# CC3220SF register map
Vendor: Texas Instruments; Series: Wireless Connectivity MCU; File version: 1
CPU: CM4 r1p0, little endian, no MPU, no FPU, 8 interrupt priority bits
Registers are 32-bit, read-write, reset 0x0 unless marked. A register's access mark holds for its fields unless they carry their own. Offsets are from the block's base; [hi:lo] are bit positions; {n}, {i} and the like mark numbered series.

## I2S
Base 0x4401C000
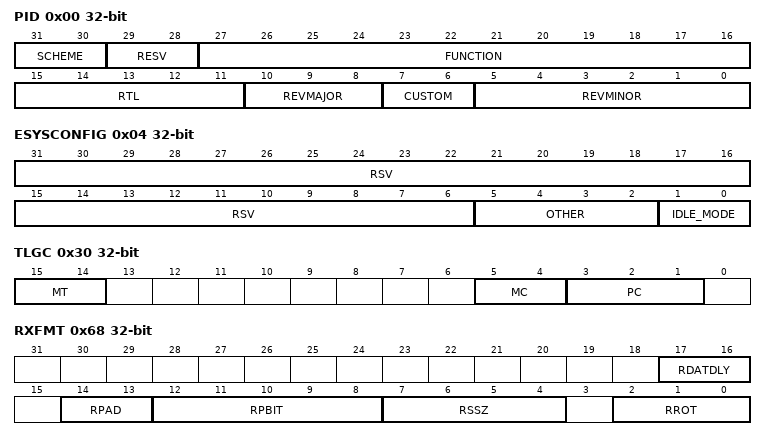
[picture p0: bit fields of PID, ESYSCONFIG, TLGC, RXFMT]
0x00 PID
  [31:30] SCHEME
  [29:28] RESV
  [27:16] FUNCTION — McASP
  [15:11] RTL
  [10:8] REVMAJOR
  [7:6] CUSTOM — non-custom
  [5:0] REVMINOR
0x04 ESYSCONFIG — Power Idle SYSCONFIG register.
  [31:6] RSV — Reserved as per PDR 3.5
  [5:2] OTHER — Reserved for future expansion
  [1:0] IDLE_MODE
0x10 PFUNC
0x14 PDIR
0x18 PDOUT
0x1C PDIN_PDSET — The pin data input register (PDIN) holds the I/O pin state of each of the McASP pins. PDIN allows the actual value of the pin to be read regardless of the state of PFUNC and PDIR. The pin data set register (PDSET) is an alias of the pin data output register (PDOUT) for writes only. Writing a 1 to the PDSET bit sets the corresponding bit in PDOUT and if PFUNC = 1 (GPIO function) and PDIR = 1 (output) drives a logic high on the pin.
0x20 PDCLR — The pin data clear register (PDCLR) is an alias of the pin data output register (PDOUT) for writes only. Writing a 1 to the PDCLR bit clears the corresponding bit in PDOUT and if PFUNC = 1 (GPIO function) and PDIR = 1 (output) drives a logic low on the pin.
0x30 TLGC — for IODFT
  [15:14] MT — MISR on/off trigger command 0x0 0x1 0x2 0x3
  [5:4] MC — States of MISR 0x0 0x1 0x2 0x3
  [3:1] PC — Pattern code 0x0 0x1 0x2 0x3 0x4 0x5 0x6 0x7
0x34 TLMR — for IODFT
0x38 TLEC — for IODFT
0x44 GBLCTL
0x48 AMUTE
  [1:0] MUTEN — AMUTE pin enable 0x0 0x1 0x2
0x4C LBCTL
  [3:2] MODE — Loop back clock source generator 0x0 0x1 0x2 0x3
0x50 TXDITCTL
0x60 GBLCTLR
0x64 RXMASK
0x68 RXFMT
  [17:16] RDATDLY — RCV Frame sync delay 0x0 0 Bit delay 0x1 1 Bit delay 0x2 2 Bit delay
  [14:13] RPAD — Pad value 0x0 0x1 0x2
  [12:8] RPBIT — Pad bit position
  [7:4] RSSZ — RCV slot Size 0x0 0x1 0x2 0x3 0x4 0x5 0x6 0x7 0x8 0x9 0xA 0xB 0xC 0xD 0xE 0xF
  [2:0] RROT — Right Rotate Value 0x0 0x1 0x2 0x3 0x4 0x5 0x6 0x7
0x6C RXFMCTL
  [15:7] RMOD — RCV Frame sync mode
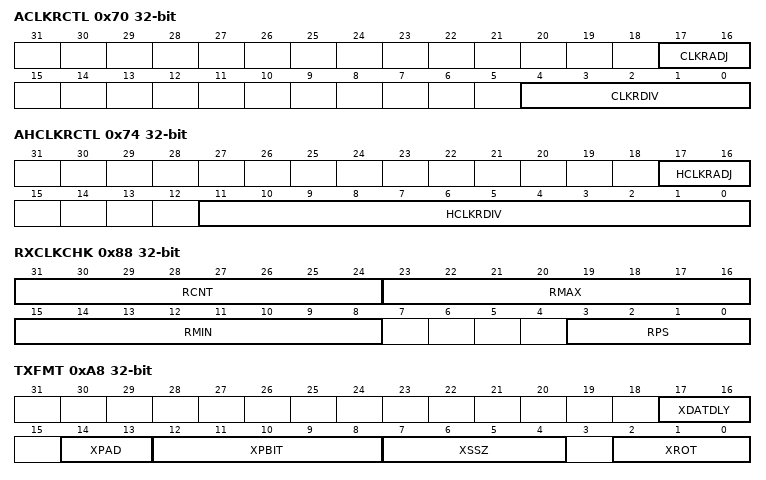
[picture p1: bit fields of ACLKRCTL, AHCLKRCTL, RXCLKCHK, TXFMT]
0x70 ACLKRCTL
  [17:16] CLKRADJ
  [4:0] CLKRDIV — RCV clock devide ratio
0x74 AHCLKRCTL
  [17:16] HCLKRADJ
  [11:0] HCLKRDIV — RCV clock Divide Ratio
0x78 RXTDM
0x7C EVTCTLR
0x80 RXSTAT
0x84 RXTDMSLOT
  [9:0] RSLOTCNT — Current RCV time slot count
0x88 RXCLKCHK
  [31:24] RCNT — RCV clock count value
  [23:16] RMAX — RCV clock maximum boundary
  [15:8] RMIN — RCV clock minimum boundary
  [3:0] RPS — RCV clock check prescaler 0x0 0x1 0x2 0x3 0x4 0x5 0x6 0x7 0x8
0x8C REVTCTL
0xA0 GBLCTLX
0xA4 TXMASK
0xA8 TXFMT
  [17:16] XDATDLY — XMT Frame sync delay 0x0 0 Bit delay 0x1 1 Bit delay 0x2 2 Bit delay
  [14:13] XPAD — Pad value 0x0 0x1 0x2
  [12:8] XPBIT — Pad bit position
  [7:4] XSSZ — XMT slot Size 0x0 0x1 0x2 0x3 0x4 0x5 0x6 0x7 0x8 0x9 0xA 0xB 0xC 0xD 0xE 0xF
  [2:0] XROT — Right Rotate Value 0x0 0x1 0x2 0x3 0x4 0x5 0x6 0x7
0xAC TXFMCTL
  [15:7] XMOD — XMT Frame sync mode
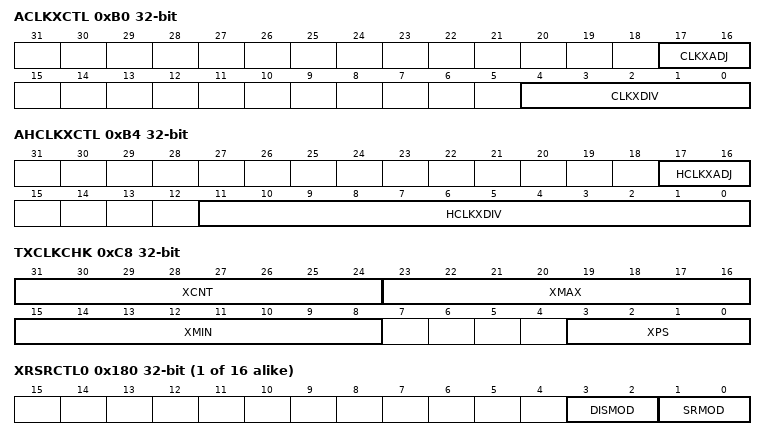
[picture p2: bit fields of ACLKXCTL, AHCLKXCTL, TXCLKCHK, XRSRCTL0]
0xB0 ACLKXCTL
  [17:16] CLKXADJ
  [4:0] CLKXDIV — XMT clock devide ratio
0xB4 AHCLKXCTL
  [17:16] HCLKXADJ
  [11:0] HCLKXDIV — XMT clock Divide Ratio
0xB8 TXTDM
0xBC EVTCTLX
0xC0 TXSTAT
0xC4 TXTDMSLOT
  [9:0] XSLOTCNT — Current XMT time slot count during reset the value of this register is 0b0101111111 (0x17f) and after reset 0
0xC8 TXCLKCHK
  [31:24] XCNT — XMT clock count value
  [23:16] XMAX — XMT clock maximum boundary
  [15:8] XMIN — XMT clock minimum boundary
  [3:0] XPS — XMT clock check prescaler 0x0 0x1 0x2 0x3 0x4 0x5 0x6 0x7 0x8
0xCC XEVTCTL
0xD0 CLKADJEN
{0x100+4i} DITCSRA{i} (i=0..5)
{0x118+4i} DITCSRB{i} (i=0..5)
{0x130+4i} DITUDRA{i} (i=0..5)
{0x148+4i} DITUDRB{i} (i=0..5)
{0x180+4i} XRSRCTL{i} (i=0..15)
  [3:2] DISMOD — Serializer drive state 0x0 Tri state 0x1 Reserved 0x2 Drive pin low 0x3 Drive pin high
  [1:0] SRMOD — Serializer Mode 0x0 InActive mode 0x1 Transmit mode 0x2 Receive mode
{0x200+4i} TXBUF{i} (i=0..15)
{0x280+4i} RXBUF{i} (i=0..15)
